# MSP430FR2433 register map
Vendor: msp430gen; File version: v0.4.0-29-g702f6f3-dirty
Registers are 16-bit, read-write, reset 0x0 unless marked. A register's access mark holds for its fields unless they carry their own. Offsets are from the block's base; [hi:lo] are bit positions; {n}, {i} and the like mark numbered series.

## ADC
Base 0x00000700
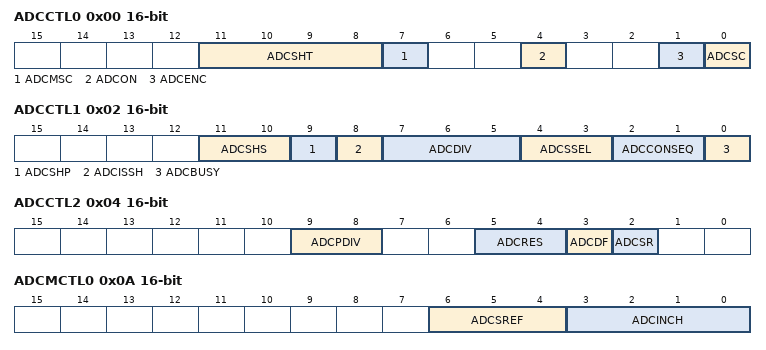
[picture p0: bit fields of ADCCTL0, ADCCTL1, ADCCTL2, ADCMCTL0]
0x00 ADCCTL0 — ADC Control 0
  [11:8] ADCSHT — ADC Sample Hold Select Bit: 0
    0=CYCLES_4 (4 ADCCLK cycles); 1=CYCLES_8 (8 ADCCLK cycles); 2=CYCLES_16 (16 ADCCLK cycles); 3=CYCLES_32 (32 ADCCLK cycles); 4=CYCLES_64 (64 ADCCLK cycles); 5=CYCLES_96 (96 ADCCLK cycles); 6=CYCLES_128 (128 ADCCLK cycles); 7=CYCLES_192 (192 ADCCLK cycles); 8=CYCLES_256 (256 ADCCLK cycles); 9=CYCLES_384 (384 ADCCLK cycles); 10=CYCLES_512 (512 ADCCLK cycles); 11=CYCLES_768 (768 ADCCLK cycles); 12=CYCLES_1024 (1024 ADCCLK cycles)
  [7] ADCMSC — ADC Multiple SampleConversion
  [4] ADCON — ADC On/enable
  [1] ADCENC — ADC Enable Conversion
  [0] ADCSC — ADC Start Conversion
0x02 ADCCTL1 — ADC Control 1
  [11:10] ADCSHS — ADC Sample/Hold Source 0
    0=SOFTWARE (ADCSC bit (software trigger)); 1=RTC (RTC event); 2=TIMER (TA1.1B)
  [9] ADCSHP — ADC Sample/Hold Pulse Mode
  [8] ADCISSH — ADC Invert Sample Hold Signal
  [7:5] ADCDIV — ADC Clock Divider Select 0
    {v}=/{v+1} (Divide by {v+1}) (v=0..7)
  [4:3] ADCSSEL — ADC Clock Source Select 0
    0=MODCLK; 1=ACLK; 2=SMCLK
  [2:1] ADCCONSEQ — ADC Conversion Sequence Select 0
    0=SINGLE (Single-channel, single-conversion: a single channel is converted once); 1=SEQUENCE (Sequence-of-channels: a sequence of channels is converted once); 2=REPEAT_SINGLE (Repeat-single-channel: a single channel is converted repeatedly); 3=REPEAT_SEQUENCE (Repeat-sequence-of-channels: a sequence of channels is converted repeatedly)
  [0] ADCBUSY
0x04 ADCCTL2 — ADC Control 2
  [9:8] ADCPDIV — ADC predivider Bit: 0
    0=/1 (Predivide by 1); 1=/4 (Predivide by 4); 2=/64 (Predivide by 64)
  [5:4] ADCRES — ADC Resolution
    0=BITS_8 (8 bit (10 clock cycle conversion time)); 1=BITS_10 (10 bit (12 clock cycle conversion time))
  [3] ADCDF — ADC Data Format
    0=UNSIGNED (Binary unsigned. Theoretically, the analog input voltage -VREF results in 0000h, and the analog input voltage +VREF results in 03FFh.); 1=SIGNED (Signed binary (2s complement), left aligned. Theoretically, the analog input voltage -VREF results in 8000h, and the analog input voltage +VREF results in 7FC0h.)
  [2] ADCSR — ADC Sampling Rate
    0=MAX_200KSPS (ADC buffer supports up to approximately 200 ksps); 1=MAX_50KSPS (ADC buffer supports up to approximately 50 ksps)
0x06 ADCLO — ADC Window Comparator Low Threshold Register
0x08 ADCHI — ADC Window Comparator High Threshold Register
0x0A ADCMCTL0 — ADC Memory Control 0
  [6:4] ADCSREF — ADC Select Reference Bit 0
    0=AVCC_AVSS (VR+ = AVCC and VR- = AVSS); 1=VREF_AVSS (VR+ = VREF and VR- = AVSS); 2=VEREF_PLUS_BUFFERED_AVSS (VR+ = VEREF+ buffered and VR- = AVSS); 3=VEREF_PLUS_AVSS (VR+ = VEREF+ and VR- = AVSS); 4=AVCC_VEREF_MINUS (VR+ = AVCC and VR- = VEREF-); 5=VREF_VEREF_MINUS (VR+ = VREF and VR- = VEREF-); 6=VEREF_PLUS_BUFFERED_VEREF_MINUS (VR+ = VEREF+ buffered and VR- = VEREF-); 7=VEREF_PLUS_VEREF_MINUS (VR+ = VEREF+ and VR- = VEREF-)
  [3:0] ADCINCH — ADC Input Channel Select Bit 0
    {v}=ADC Input Channel {v} (v=0..15)
0x12 ADCMEM0 — ADC Conversion Memory 0
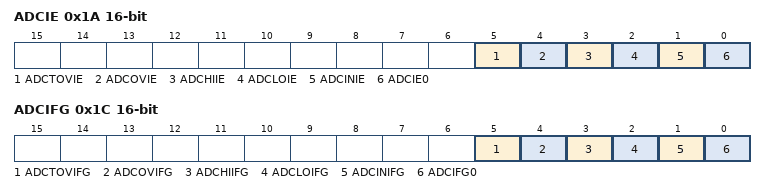
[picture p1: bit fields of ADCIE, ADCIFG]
0x1A ADCIE — ADC Interrupt Enable
  [5] ADCTOVIE — ADC conversion-time-overflow Interrupt enable
  [4] ADCOVIE — ADC ADCMEM overflow Interrupt enable
  [3] ADCHIIE — ADC Interrupt enable for upper threshold of the Window comparator
  [2] ADCLOIE — ADC Interrupt enable for lower threshold of the Window comparator
  [1] ADCINIE — ADC Interrupt enable for the inside of window of the Window comparator
  [0] ADCIE0 — ADC Interrupt enable
0x1C ADCIFG — ADC Interrupt Flag
  [5] ADCTOVIFG — ADC conversion-time-overflow Interrupt Flag
  [4] ADCOVIFG — ADC ADCMEM overflow Interrupt Flag
  [3] ADCHIIFG — ADC Interrupt Flag for upper threshold of the Window comparator
  [2] ADCLOIFG — ADC Interrupt Flag for lower threshold of the Window comparator
  [1] ADCINIFG — ADC Interrupt Flag for the inside of window of the Window comparator
  [0] ADCIFG0 — ADC Interrupt Flag
0x1E ADCIV — ADC Interrupt Vector Word
  [15:0] ADCIV — ADC interrupt vector value
    0=NONE (No interrupt pending); 2=OVERFLOW (Interrupt Source: ADCMEM0 overflow; Interrupt Flag: ADCOVIFG; Interrupt Priority: Highest); 4=TIME_OVERFLOW (Interrupt Source: Conversion time overflow; Interrupt Flag: ADCTOVIFG); 6=ABOVE_WINDOW (Interrupt Source: ADCHI Interrupt flag; Interrupt Flag: ADCHIIFG); 8=BELOW_WINDOW (Interrupt Source: ADCLO Interrupt flag; Interrupt Flag: ADCLOIFG); 10=INSIDE_WINDOW (Interrupt Source: ADCIN Interrupt flag; Interrupt Flag: ADCINIFG); 12=RESULT_READY (Interrupt Source: ADC memory Interrupt flag; Interrupt Flag: ADCIFG0; Interrupt Priority: Lowest)
